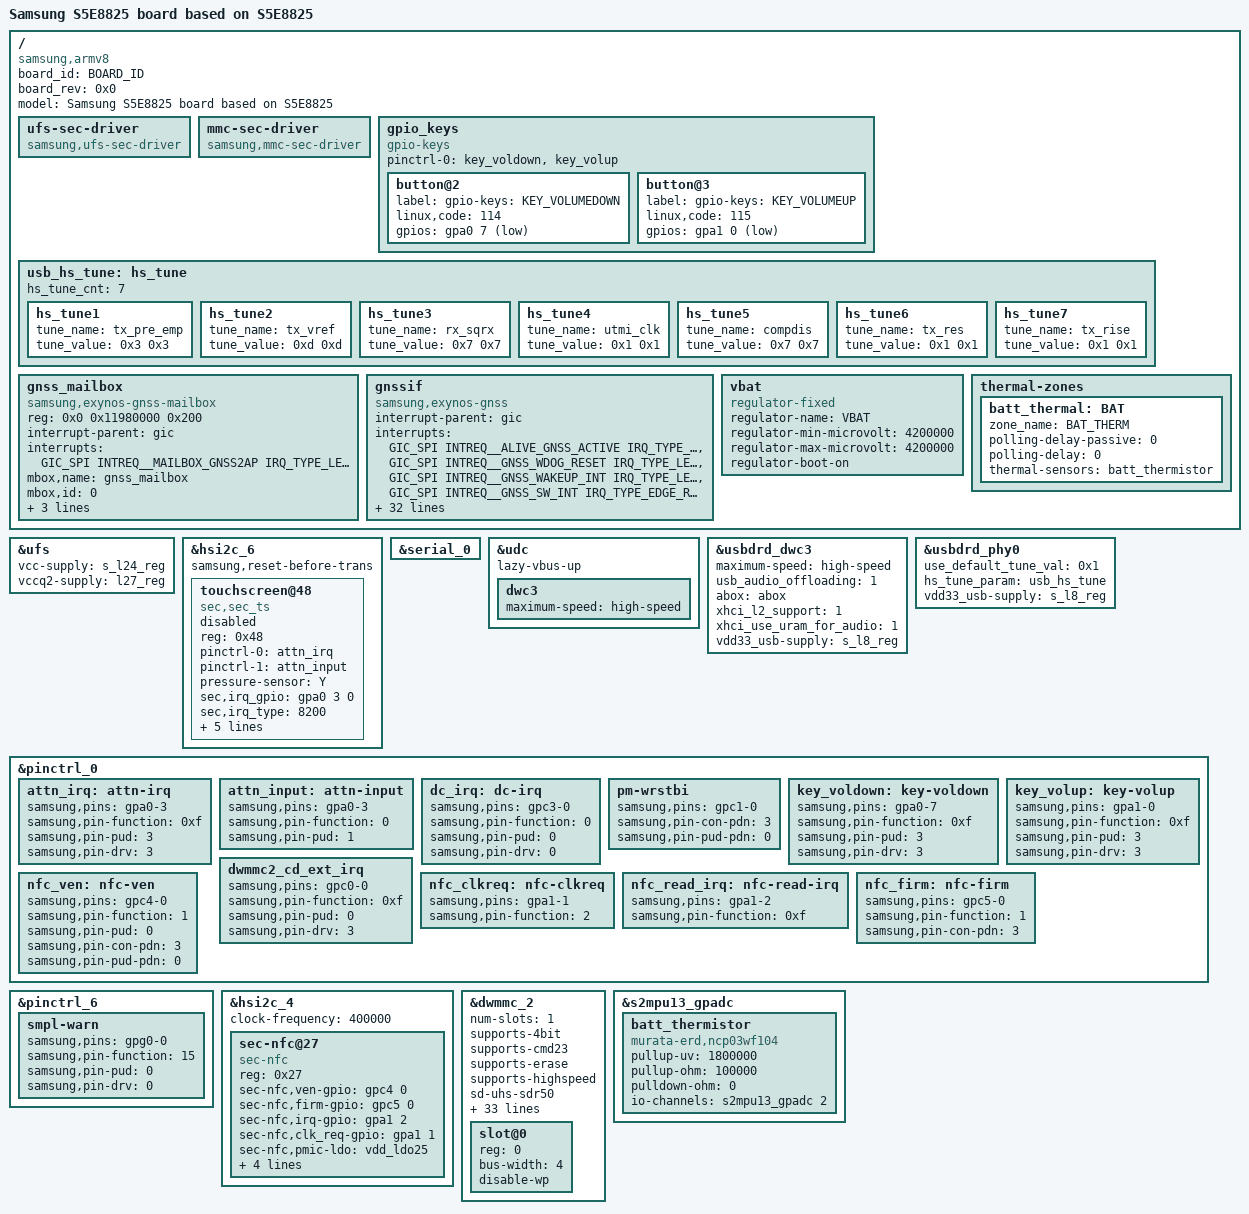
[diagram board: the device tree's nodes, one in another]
/*
 * SAMSUNG S5E8825 SoC device tree source
 *
 * Copyright (c) 2020 Samsung Electronics Co., Ltd.
 *             http://www.samsung.com
 *
 * SAMSUNG S5E8825 SoC device nodes are listed in this file.
 * EXYNOS based board files can include this file and provide
 * values for board specfic bindings.
 *
 * This program is free software; you can redistribute it and/or modify
 * it under the terms of the GNU General Public License version 2 as
 * published by the Free Software Foundation.
 */

#include <dt-bindings/interrupt-controller/s5e8825.h>
#include <dt-bindings/gpio/gpio.h>
#include <dt-bindings/clock/s5e8825.h>
#include "../erd/s5e8825-cp-s5308ap-sipc.dtsi"
//#include "../erd/camera/s5e8825-erd8825-camera.dtsi"
#include "../erd/s5e8825-erd8825-dit.dtsi"
#include "../erd/s5e8825-erd8825-mfc.dtsi"
#include "sec_reboot.dtsi"
#include "s5e8825_samsung_debug.dtsi"

#define BOARD_ID        0x0

/ {
	compatible = "samsung,armv8", "samsung,s5e8825";
	board_id = <BOARD_ID>;
	board_rev = <0x0>;

	fragment@model {
		target-path = "/";
		__overlay__ {
			#address-cells = <2>;
			#size-cells = <1>;

			model = "Samsung S5E8825 board based on S5E8825";

			ufs-sec-driver {
			      compatible = "samsung,ufs-sec-driver";
			      status = "okay";
			};

			mmc-sec-driver {
			      compatible = "samsung,mmc-sec-driver";
			      status = "okay";
			};

			gpio_keys {
				status = "okay";
				compatible = "gpio-keys";
				pinctrl-names = "default";
				pinctrl-0 = <&key_voldown &key_volup>;

				button@2 {
					label = "gpio-keys: KEY_VOLUMEDOWN";
					linux,code = <114>;
					gpios = <&gpa0 7 0xf>;
				};
				button@3 {
					label = "gpio-keys: KEY_VOLUMEUP";
					linux,code = <115>;
					gpios = <&gpa1 0 0xf>;
				};
			};

			usb_hs_tune:hs_tune {
				hs_tune_cnt = <7>;
				/* value = <device host> */
				hs_tune1 {
					tune_name = "tx_pre_emp";
					tune_value = <0x3 0x3>;
				};

				hs_tune2 {
					tune_name = "tx_vref";
					tune_value = <0xd 0xd>;
				};

				hs_tune3 {
					tune_name = "rx_sqrx";
					tune_value = <0x7 0x7>;
				};

				hs_tune4 {
					tune_name = "utmi_clk";
					tune_value = <0x1 0x1>;
				};

				hs_tune5 {
					tune_name = "compdis";
					tune_value = <0x7 0x7>;
				};

				hs_tune6 {
					tune_name = "tx_res";
					tune_value = <0x1 0x1>;
				};

				hs_tune7 {
					tune_name = "tx_rise";
					tune_value = <0x1 0x1>;
				};
			};

/*			usb_notifier {
				compatible = "samsung,usb-notifier";
				udc = <&udc>;
				status = "okay";
			};
*/
			gnss_mailbox: gnss_mailbox {
				status = "okay";
				compatible = "samsung,exynos-gnss-mailbox";

				reg = <0x0 0x11980000 0x200>; /* MAILBOX AP2GNSS */

				interrupt-parent = <&gic>;
				interrupts = <GIC_SPI INTREQ__MAILBOX_GNSS2AP IRQ_TYPE_LEVEL_HIGH>;

				mbox,name = "gnss_mailbox";
				mbox,id = <0>;

				num_shared_reg = <4>;
				shared_reg_offset = <0x100>;
				use_sw_reset_reg = <0>;
			};

			gnssif {
				status = "okay";
				compatible = "samsung,exynos-gnss";

				interrupt-parent = <&gic>;
				interrupts = <GIC_SPI INTREQ__ALIVE_GNSS_ACTIVE IRQ_TYPE_LEVEL_HIGH>,
					<GIC_SPI INTREQ__GNSS_WDOG_RESET IRQ_TYPE_LEVEL_HIGH>,
					<GIC_SPI INTREQ__GNSS_WAKEUP_INT IRQ_TYPE_LEVEL_HIGH>,
					<GIC_SPI INTREQ__GNSS_SW_INT IRQ_TYPE_EDGE_RISING>;

				interrupt-names = "ACTIVE", "WATCHDOG", "WAKEUP", "SW_INIT";
				shmem,name = "KEPLER";
				device_node_name = "gnss_ipc";

				/* Mailbox */
				mbox_info = <&gnss_mailbox>;

				/* ap2gnss */
				mbx,int_bcmd = <0>;
				mbx,int_req_fault_info = <1>;
				mbx,int_ipc_msg = <2>;
				mbx,int_ack_wake_set = <3>;
				mbx,int_ack_wake_clr = <4>;

				/* gnss2ap */
				mbx,irq_bcmd = <0>;
				mbx,irq_rsp_fault_info = <1>;
				mbx,irq_ipc_msg = <2>;
				mbx,irq_req_wake_clr = <4>;
				mbx,irq_simple_lock = <15>;

				mbx,reg_bcmd_ctrl = <0>, <1>, <2>, <3>;

				/* Memory */
				memory-region = <&gnss_rmem>;

				reg_rx_ipc_msg = <1 5>;
				reg_tx_ipc_msg = <1 4>;
				reg_rx_head = <1 3>;
				reg_rx_tail = <1 2>;
				reg_tx_head = <1 1>;
				reg_tx_tail = <1 0>;
				fault_info = <1 0x200000 0x180000>;

				shmem,code_offset = <0x00000000>;
				shmem,code_allowed_size = <0x00380000>;
				shmem,ipc_offset = <0x00380000>;
				shmem,ipc_size = <0x00080000>;
				shmem,ipc_rx_offset = <0x00000000>;
				shmem,ipc_rx_size = <0x00040000>;
				shmem,ipc_tx_offset = <0x00040000>;
				shmem,ipc_tx_size = <0x0003FF80>;
				shmem,ipc_reg_offset = <0x0007FF80>;
				shmem,ipc_reg_size = <0x00000080>; /* can afford 32 regs */
			}; /* end of gnssif */

			vbat: vbat {
				compatible = "regulator-fixed";
				regulator-name = "VBAT";
				regulator-min-microvolt = <4200000>;
				regulator-max-microvolt = <4200000>;
				regulator-boot-on;
			};

			thermal-zones {
				batt_thermal: BAT {
					zone_name  = "BAT_THERM";
					polling-delay-passive = <0>;
					polling-delay = <0>;
					thermal-sensors = <&batt_thermistor>;
				};
			};
		};
	};
};

&ufs {
	vcc-supply = <&s_l24_reg>;
	vccq2-supply = <&l27_reg>;
};

&hsi2c_6 {
	#address-cells = <1>;
	#size-cells = <0>;
	status = "okay";
	samsung,reset-before-trans;
	touchscreen@48 {
		status = "disabled";
		compatible = "sec,sec_ts";
		reg = <0x48>;
		pinctrl-names = "on_state", "off_state";
		pinctrl-0 = <&attn_irq>;
		pinctrl-1 = <&attn_input>;
		pressure-sensor = "Y";
		sec,irq_gpio = <&gpa0 3 0>;
		sec,irq_type = <8200>;
		sec,max_coords = <4095 4095>;
		sec,mis_cal_check = <1>;
		// dvdd-supply = <&dp_ldo2>;// VDD_TSP0_1P8
		// avdd-supply = <&dp_ldo3>;// VDD_TSP0_3P0
		sec,regulator_boot_on;
		sec,always_lpmode = <1>;
		sec,project_name = "papaya";
	};
};

&serial_0 {
	status = "okay";
};

&udc {
	status = "okay";
	lazy-vbus-up;
	dwc3 {
		maximum-speed = "high-speed";
	};
};

&usbdrd_dwc3 {
	status = "okay";
	maximum-speed = "high-speed";
	usb_audio_offloading = <1>;
	abox = <&abox>;
	xhci_l2_support = <1>;
	xhci_use_uram_for_audio = <1>;
	vdd33_usb-supply = <&s_l8_reg>;
};

&usbdrd_phy0 {
	status = "okay";
	use_default_tune_val = <0x1>;
	hs_tune_param = <&usb_hs_tune>;
	vdd33_usb-supply = <&s_l8_reg>;
};

&pinctrl_0
{
	attn_irq: attn-irq {
		samsung,pins = "gpa0-3";
		samsung,pin-function = <0xf>;
		samsung,pin-pud = <3>;
		samsung,pin-drv = <3>;
	};

	attn_input: attn-input {
		samsung,pins = "gpa0-3";
		samsung,pin-function = <0>;
		samsung,pin-pud = <1>;
	};

	dc_irq: dc-irq {
		samsung,pins = "gpc3-0";
		samsung,pin-function = <0>;
		samsung,pin-pud = <0>;
		samsung,pin-drv = <0>;
	};

	pm-wrstbi {
		   samsung,pins = "gpc1-0";
		   samsung,pin-con-pdn = <3>;
		   samsung,pin-pud-pdn = <0>;
	};

	key_voldown: key-voldown {
		samsung,pins = "gpa0-7";
		samsung,pin-function = <0xf>;
		samsung,pin-pud = <3>;
		samsung,pin-drv = <3>;
	};

	key_volup: key-volup {
		samsung,pins = "gpa1-0";
		samsung,pin-function = <0xf>;
		samsung,pin-pud = <3>;
		samsung,pin-drv = <3>;
	};

	dwmmc2_cd_ext_irq: dwmmc2_cd_ext_irq {
		samsung,pins = "gpc0-0";
		samsung,pin-function = <0xf>;
		samsung,pin-pud = <0>;
		samsung,pin-drv = <3>;
	};
};

&pinctrl_6 {
	smpl-warn {
		   samsung,pins = "gpg0-0";
		   samsung,pin-function = <15>;
		   samsung,pin-pud = <0>;
		   samsung,pin-drv = <0>;
	};
};

&pinctrl_0 {
	nfc_clkreq: nfc-clkreq {
	samsung,pins ="gpa1-1";
	samsung,pin-function = <2>;
	};
	nfc_read_irq: nfc-read-irq {
		samsung,pins ="gpa1-2";
		samsung,pin-function = <0xf>;
	};
};

&pinctrl_0 {
	nfc_ven: nfc-ven {
		samsung,pins ="gpc4-0";
		samsung,pin-function = <1>;
		samsung,pin-pud = <0>;
		samsung,pin-con-pdn =<3>;
		samsung,pin-pud-pdn = <0>;
	};
	nfc_firm: nfc-firm {
		samsung,pins ="gpc5-0";
		samsung,pin-function = <1>;
		samsung,pin-con-pdn =<3>;
	};
};

&hsi2c_4 {
	#address-cells = <1>;
	#size-cells = <0>;
	status = "okay";
	clock-frequency = <400000>;

	sec-nfc@27 {
		compatible = "sec-nfc";
		reg = <0x27>;

		sec-nfc,ven-gpio = <&gpc4 0 0>;
		sec-nfc,firm-gpio = <&gpc5 0 0>;
		sec-nfc,irq-gpio = <&gpa1 2 0>;
		sec-nfc,clk_req-gpio = <&gpa1 1 0>;
		sec-nfc,pmic-ldo = "vdd_ldo25";

		clock-names = "OSC_NFC";
		clkctrl-reg = <0x11860a0c>;
		clocks = <&clock OSC_NFC>;

		pinctrl-names = "default";
		pinctrl-0 = <&xclkout1 &nfc_ven &nfc_clkreq &nfc_read_irq &nfc_firm>;
	};
};

&dwmmc_2 {
	#address-cells = <1>;
	#size-cells = <0>;
	status = "okay";
	num-slots = <1>;
	supports-4bit;
	supports-cmd23;
	supports-erase;
	supports-highspeed;
	sd-uhs-sdr50;
	sd-uhs-sdr104;
	card-detect-gpio;
	bypass-for-allpass;
	use-fine-tuning;
	use-phase-detect;
	card-init-hwacg-ctrl;
	skip-init-mmc-scan;
	ssc-rate-mfr = <4>;
	ssc-rate-mrr = <27>;
	qos-dvfs-level = <400000>;
	fifo-depth = <0x40>;
	desc-size = <4>;
	card-detect-delay = <200>;
	data-timeout = <200>;
	hto-timeout = <80>;
	samsung,dw-mshc-ciu-div = <3>;
	clock-frequency = <800000000>;
	samsung,dw-mshc-sdr-timing = <3 0 2 1>;
	samsung,dw-mshc-ddr-timing = <3 0 2 1>;
	samsung,dw-mshc-sdr50-timing = <3 0 4 2>;
	samsung,dw-mshc-sdr104-timing = <3 0 3 0>;

	num-ref-clks = <9>;
	ciu_clkin = <25 50 50 25 50 100 200 50 50>;

	/* Swapping clock drive strength */
	clk-drive-number = <6>;
	pinctrl-names = "default",
			"fast-slew-rate-1x",
			"fast-slew-rate-2x",
			"fast-slew-rate-3x",
			"fast-slew-rate-4x",
			"fast-slew-rate-5x",
			"fast-slew-rate-6x";
	pinctrl-0 = <&sd2_clk &sd2_cmd &sd2_bus1 &sd2_bus4 &dwmmc2_cd_ext_irq>;
	pinctrl-1 = <&sd2_clk_fast_slew_rate_1x>;
	pinctrl-2 = <&sd2_clk_fast_slew_rate_2x>;
	pinctrl-3 = <&sd2_clk_fast_slew_rate_3x>;
	pinctrl-4 = <&sd2_clk_fast_slew_rate_4x>;
	pinctrl-5 = <&sd2_clk_fast_slew_rate_5x>;
	pinctrl-6 = <&sd2_clk_fast_slew_rate_6x>;

	card-detect = <&gpc0 0 0xf>;
	slot@0 {
		reg = <0>;
		bus-width = <4>;
		disable-wp;
	};
};

&s2mpu13_gpadc {
	batt_thermistor: batt_thermistor {
		compatible = "murata-erd,ncp03wf104";
		status = "okay";
		pullup-uv = <1800000>;
		pullup-ohm = <100000>;
		pulldown-ohm = <0>;
		io-channels = <&s2mpu13_gpadc 2>;
		io-channel-names = "batt_therm";
		#thermal-sensor-cells = <0>;
	};
};
